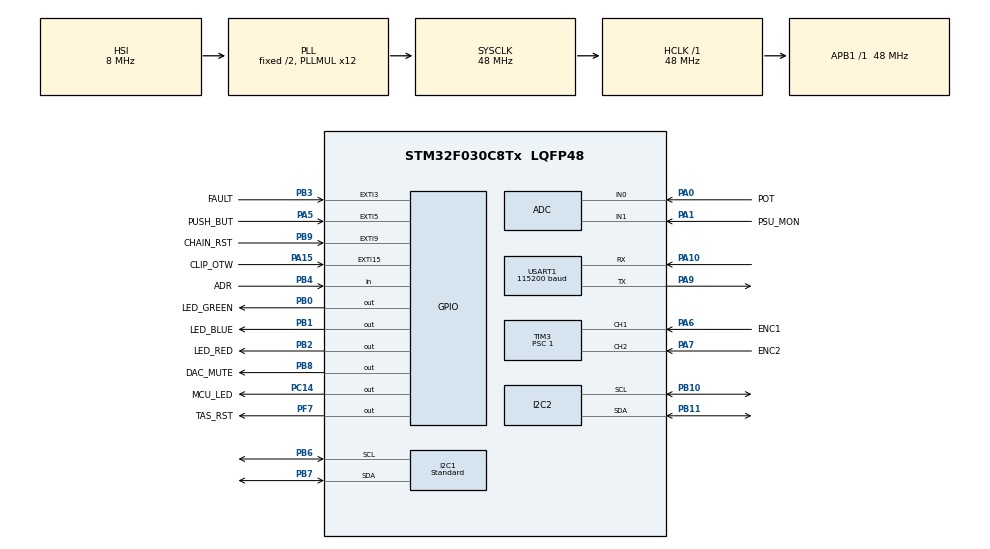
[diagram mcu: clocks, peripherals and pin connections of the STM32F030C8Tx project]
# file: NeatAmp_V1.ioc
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ADC.AWD1HighThreshold=0x0D90
ADC.AWD1LowThreshold=0x0BF0
ADC.ContinuousConvMode=DISABLE
ADC.DMAContinuousRequests=ENABLE
ADC.EnableAnalogWatchDog=true
ADC.ExternalTrigConv=ADC_EXTERNALTRIGCONV_T1_TRGO
ADC.ITMode=ENABLE
ADC.SamplingTime=ADC_SAMPLETIME_13CYCLES_5
ADC.WatchdogChannel=ADC_CHANNEL_1
CRC.DefaultInitValueUse=DEFAULT_INIT_VALUE_ENABLE
Dma.ADC.0.Direction=DMA_PERIPH_TO_MEMORY
Dma.ADC.0.Instance=DMA1_Channel1
Dma.ADC.0.MemDataAlignment=DMA_MDATAALIGN_HALFWORD
Dma.ADC.0.MemInc=DMA_MINC_ENABLE
Dma.ADC.0.Mode=DMA_CIRCULAR
Dma.ADC.0.PeriphDataAlignment=DMA_PDATAALIGN_HALFWORD
Dma.ADC.0.PeriphInc=DMA_PINC_DISABLE
Dma.ADC.0.Priority=DMA_PRIORITY_MEDIUM
Dma.Request0=ADC
I2C1.Analog_Filter=I2C_ANALOGFILTER_DISABLE
I2C1.I2C_Speed_Mode=I2C_Standard
I2C1.Speed=100
I2C1.Timing=0x00B0DBFF
I2C2.Timing=0x20303E5D
Mcu.Family=STM32F0
Mcu.Name=STM32F030C8Tx
Mcu.Package=LQFP48
NVIC.ADC1_IRQn=true\:3\:0\:true\:false\:true\:true\:true\:true
NVIC.DMA1_Channel1_IRQn=true\:3\:0\:true\:false\:true\:false\:true\:true
NVIC.EXTI2_3_IRQn=true\:1\:0\:true\:false\:true\:true\:true\:true
NVIC.EXTI4_15_IRQn=true\:2\:0\:true\:false\:true\:true\:true\:true
NVIC.USART1_IRQn=true\:2\:0\:true\:false\:true\:true\:true\:true
PA0.GPIO_Label=POT
PA0.Mode=IN0
PA0.Signal=ADC_IN0
PA1.GPIO_Label=PSU_MON
PA1.Mode=IN1
PA1.Signal=ADC_IN1
PA10.Mode=Asynchronous
PA10.Signal=USART1_RX
PA13.Mode=Serial_Wire
PA13.Signal=SYS_SWDIO
PA14.Mode=Serial_Wire
PA14.Signal=SYS_SWCLK
PA15.GPIO_Label=CLIP_OTW
PA15.GPIO_ModeDefaultEXTI=GPIO_MODE_IT_RISING_FALLING
PA15.Signal=GPXTI15
PA5.GPIO_Label=PUSH_BUT
PA5.GPIO_PuPd=GPIO_PULLUP
PA5.Signal=GPXTI5
PA6.GPIO_Label=ENC1
PA6.GPIO_PuPd=GPIO_PULLUP
PA6.Signal=S_TIM3_CH1
PA7.GPIO_Label=ENC2
PA7.GPIO_PuPd=GPIO_PULLUP
PA7.Signal=S_TIM3_CH2
PA9.Mode=Asynchronous
PA9.Signal=USART1_TX
PB0.GPIO_Label=LED_GREEN
PB0.GPIO_ModeDefaultOutputPP=GPIO_MODE_OUTPUT_PP
PB0.Signal=GPIO_Output
PB1.GPIO_Label=LED_BLUE
PB1.GPIO_ModeDefaultOutputPP=GPIO_MODE_OUTPUT_PP
PB1.Signal=GPIO_Output
PB10.GPIO_Pu=GPIO_PULLUP
PB10.Mode=I2C
PB10.Signal=I2C2_SCL
PB11.GPIO_Pu=GPIO_PULLUP
PB11.Mode=I2C
PB11.Signal=I2C2_SDA
PB2.GPIO_Label=LED_RED
PB2.GPIO_ModeDefaultOutputPP=GPIO_MODE_OUTPUT_PP
PB2.Signal=GPIO_Output
PB3.GPIO_Label=FAULT
PB3.GPIO_ModeDefaultEXTI=GPIO_MODE_IT_FALLING
PB3.Signal=GPXTI3
PB4.GPIO_Label=ADR
PB4.Signal=GPIO_Input
PB6.GPIO_FM6=SYSCFG_CFGR1_I2C_FMP_PB6
PB6.GPIO_Pu=GPIO_PULLUP
PB6.Mode=I2C
PB6.Signal=I2C1_SCL
PB7.GPIO_FM7=SYSCFG_CFGR1_I2C_FMP_PB7
PB7.GPIO_Pu=GPIO_PULLUP
PB7.Mode=I2C
PB7.Signal=I2C1_SDA
PB8.GPIO_FM8=SYSCFG_CFGR1_I2C_FMP_PB8
PB8.GPIO_Label=DAC_MUTE
PB8.GPIO_Speed=GPIO_SPEED_FREQ_HIGH
PB8.PinState=GPIO_PIN_RESET
PB8.Signal=GPIO_Output
PB9.GPIO_Label=CHAIN_RST
PB9.Signal=GPXTI9
PC14-OSC32_IN.GPIO_Label=MCU_LED
PC14-OSC32_IN.GPIO_ModeDefaultOutputPP=GPIO_MODE_OUTPUT_OD
PC14-OSC32_IN.GPIO_Speed=GPIO_SPEED_FREQ_LOW
PC14-OSC32_IN.PinState=GPIO_PIN_SET
PC14-OSC32_IN.Signal=GPIO_Output
PF7.GPIO_Label=TAS_RST
PF7.GPIO_Speed=GPIO_SPEED_FREQ_HIGH
PF7.PinState=GPIO_PIN_RESET
PF7.Signal=GPIO_Output
ProjectManager.HeapSize=0x100
ProjectManager.StackSize=0x400
ProjectManager.TargetToolchain=STM32CubeIDE
RCC.AHBFreq_Value=48000000
RCC.APB1Freq_Value=48000000
RCC.APB1TimFreq_Value=48000000
RCC.HCLKFreq_Value=48000000
RCC.I2c1ClockSelection=RCC_I2C1CLKSOURCE_SYSCLK
RCC.PLLMUL=RCC_PLL_MUL12
RCC.SYSCLKFreq_VALUE=48000000
RCC.SYSCLKSource=RCC_SYSCLKSOURCE_PLLCLK
RCC.Usart1ClockSelection=RCC_USART1CLKSOURCE_SYSCLK
SH.S_TIM3_CH1.0=TIM3_CH1,Encoder_Interface
SH.S_TIM3_CH2.0=TIM3_CH2,Encoder_Interface
TIM1.Period=9
TIM1.Prescaler=47999
TIM1.TIM_MasterOutputTrigger=TIM_TRGO_UPDATE
TIM3.IC1Filter=15
TIM3.IC1Polarity=TIM_ICPOLARITY_FALLING
TIM3.IC2Filter=15
TIM3.IC2Polarity=TIM_ICPOLARITY_FALLING
TIM3.Period=0xFFFF
TIM3.Prescaler=1
TIM6.Period=0xFFFF
TIM6.Prescaler=47999
USART1.BaudRate=115200
USART1.VirtualMode-Asynchronous=VM_ASYNC
USART1.WordLength=WORDLENGTH_8B
VP_CRC_VS_CRC.Mode=CRC_Activate
VP_TIM1_VS_ClockSourceINT.Mode=Internal
VP_TIM6_VS_ClockSourceINT.Mode=Enable_Timer
board=custom

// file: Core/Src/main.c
/* USER CODE BEGIN Header */
/*
 * *****************************************************************************
 * NeatAmp software
 *
 * main.c
 *
 * Author :  AIM65
 * Date : 6 Avr 2020
 * (c) AIM65
 *
 * Made with ST CubeMX and ST CubeIDE
 *
 * *****************************************************************************
*/

/**
  ******************************************************************************
  * @file           : main.c
  * @brief          : Main program body
  ******************************************************************************
  * @attention
  *
  * <h2><center>&copy; Copyright (c) 2020 STMicroelectronics.
  * All rights reserved.</center></h2>
  *
  * This software component is licensed by ST under BSD 3-Clause license,
  * the "License"; You may not use this file except in compliance with the
  * License. You may obtain a copy of the License at:
  *                        opensource.org/licenses/BSD-3-Clause
  *
  ******************************************************************************
  */
/* USER CODE END Header */
#include "main.h"
#include "adc.h"
#include "crc.h"
#include "dma.h"
#include "i2c.h"
#include "tim.h"
#include "usart.h"
#include "gpio.h"

/* USER CODE BEGIN Includes */
#include "amp_board.h"
#include "neatamp.h"

/* USER CODE END Includes */

void SystemClock_Config(void);

int main(void)
{

  /* MCU Configuration--------------------------------------------------------*/

  /* Reset of all peripherals, Initializes the Flash interface and the Systick. */
  HAL_Init();

  /* Configure the system clock */
  SystemClock_Config();

  /* Initialize all configured peripherals */
  MX_GPIO_Init();
  MX_DMA_Init();
  MX_ADC_Init();
  MX_I2C1_Init();
  MX_I2C2_Init();
  MX_USART1_UART_Init();
  MX_TIM3_Init();
  MX_CRC_Init();
  MX_TIM1_Init();
  MX_TIM6_Init();
  /* USER CODE BEGIN 2 */

  AMP_Init();

  /* USER CODE END 2 */

  /* Infinite loop */
  /* USER CODE BEGIN WHILE */
  while (1)
  {
	Manage_serial_event();
	Manage_supervision_event();
	Manage_UI_event();
	if (TimeCounter(Get_tmr2,0) == 0)
	 {
	  //Relaunch timer and toggle MCU_LED
	  TimeCounter(Launch_tmr2, 75);
	  HAL_GPIO_TogglePin(MCU_LED_GPIO_Port, MCU_LED_Pin);
	 }

    /* USER CODE END WHILE */

  }
}

void SystemClock_Config(void)
{
  RCC_OscInitTypeDef RCC_OscInitStruct = {0};
  RCC_ClkInitTypeDef RCC_ClkInitStruct = {0};
  RCC_PeriphCLKInitTypeDef PeriphClkInit = {0};

  /** Initializes the RCC Oscillators according to the specified parameters
  * in the RCC_OscInitTypeDef structure.
  */
  RCC_OscInitStruct.OscillatorType = RCC_OSCILLATORTYPE_HSI|RCC_OSCILLATORTYPE_HSI14;
  RCC_OscInitStruct.HSIState = RCC_HSI_ON;
  RCC_OscInitStruct.HSI14State = RCC_HSI14_ON;
  RCC_OscInitStruct.HSICalibrationValue = RCC_HSICALIBRATION_DEFAULT;
  RCC_OscInitStruct.HSI14CalibrationValue = 16;
  RCC_OscInitStruct.PLL.PLLState = RCC_PLL_ON;
  RCC_OscInitStruct.PLL.PLLSource = RCC_PLLSOURCE_HSI;
  RCC_OscInitStruct.PLL.PLLMUL = RCC_PLL_MUL12;
  RCC_OscInitStruct.PLL.PREDIV = RCC_PREDIV_DIV1;
  if (HAL_RCC_OscConfig(&RCC_OscInitStruct) != HAL_OK)
  {
    Error_Handler();
  }
  /** Initializes the CPU, AHB and APB buses clocks
  */
  RCC_ClkInitStruct.ClockType = RCC_CLOCKTYPE_HCLK|RCC_CLOCKTYPE_SYSCLK
                              |RCC_CLOCKTYPE_PCLK1;
  RCC_ClkInitStruct.SYSCLKSource = RCC_SYSCLKSOURCE_PLLCLK;
  RCC_ClkInitStruct.AHBCLKDivider = RCC_SYSCLK_DIV1;
  RCC_ClkInitStruct.APB1CLKDivider = RCC_HCLK_DIV1;

  if (HAL_RCC_ClockConfig(&RCC_ClkInitStruct, FLASH_LATENCY_1) != HAL_OK)
  {
    Error_Handler();
  }
  PeriphClkInit.PeriphClockSelection = RCC_PERIPHCLK_USART1|RCC_PERIPHCLK_I2C1;
  PeriphClkInit.Usart1ClockSelection = RCC_USART1CLKSOURCE_SYSCLK;
  PeriphClkInit.I2c1ClockSelection = RCC_I2C1CLKSOURCE_SYSCLK;
  if (HAL_RCCEx_PeriphCLKConfig(&PeriphClkInit) != HAL_OK)
  {
    Error_Handler();
  }
}

void Error_Handler(void)
{
}

/************************ (C) COPYRIGHT STMicroelectronics *****END OF FILE****/
